# LPC18xx register map
File version: 18
Registers are 32-bit, read-write, reset 0x0 unless marked. A register's access mark holds for its fields unless they carry their own. Offsets are from the block's base; [hi:lo] are bit positions; {n}, {i} and the like mark numbered series.

## TIMER0 — Product name title=UM10430 Chapter title=LPC18xx Timer0/1/2/3 Modification date=1/14/2011 Major revision=0 Minor revision=7
Base 0x40084000
Same registers: TIMER1 0x40085000, TIMER2 0x400C3000, TIMER3 0x400C4000
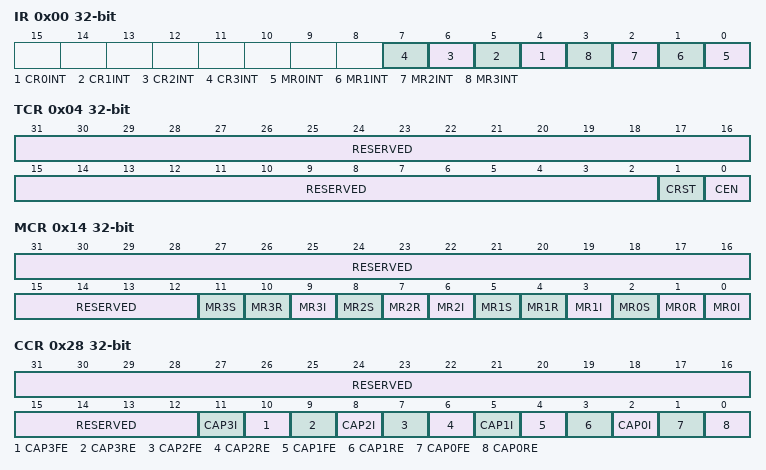
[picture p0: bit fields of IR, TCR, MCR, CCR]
0x00 IR — Interrupt Register. The IR can be written to clear interrupts. The IR can be read to identify which of eight possible interrupt sources are pending.
  [n+4] CR{n}INT (n=0..3) — Interrupt flag for capture channel {n} event.
  [n] MR{n}INT (n=0..3) — Interrupt flag for match channel {n}.
0x04 TCR — Timer Control Register. The TCR is used to control the Timer Counter functions. The Timer Counter can be disabled or reset through the TCR.
  [31:2] RESERVED — Reserved, user software should not write ones to reserved bits. The value read from a reserved bit is not defined.
  [1] CRST — When one, the Timer Counter and the Prescale Counter are synchronously reset on the next positive edge of PCLK. The counters remain reset until TCR[1] is returned to zero.
  [0] CEN — When one, the Timer Counter and Prescale Counter are enabled for counting. When zero, the counters are disabled.
0x08 TC — Timer Counter. The 32 bit TC is incremented every PR+1 cycles of PCLK. The TC is controlled through the TCR.
  [31:0] TC — Timer counter value.
0x0C PR — Prescale Register. The Prescale Counter (below) is equal to this value, the next clock increments the TC and clears the PC.
  [31:0] PM — Prescale counter maximum value.
0x10 PC — Prescale Counter. The 32 bit PC is a counter which is incremented to the value stored in PR. When the value in PR is reached, the TC is incremented and the PC is cleared. The PC is observable and controllable through the bus interface.
  [31:0] PC — Prescale counter value.
0x14 MCR — Match Control Register. The MCR is used to control if an interrupt is generated and if the TC is reset when a Match occurs.
  [31:12] RESERVED — Reserved, user software should not write ones to reserved bits. The value read from a reserved bit is not defined.
  [11] MR3S — Stop on MR3
    1=TC_AND_PC_WILL_BE_ST (TC and PC will be stopped and TCR[0] will be set to 0 if MR3 matches the TC.); 0=FEATURE_DISABLED_
  [3n+1] MR{n}R (n=0..3) — Reset on MR{n}
    1=TC_WILL_BE_RESET_IF_ (TC will be reset if MR{n} matches it.); 0=FEATURE_DISABLED_
  [9] MR3I — Interrupt on MR3
    1=INTERRUPT_IS_GENERAT (Interrupt is generated when MR3 matches the value in the TC.); 0=THIS_INTERRUPT_IS_DI (This interrupt is disabled)
  [8] MR2S — Stop on MR2.
    1=TC_AND_PC_WILL_BE_ST (TC and PC will be stopped and TCR[0] will be set to 0 if MR2 matches the TC); 0=FEATURE_DISABLED_
  [6] MR2I — Interrupt on MR2
    1=INTERRUPT_IS_GENERAT (Interrupt is generated when MR2 matches the value in the TC.); 0=INTERRUPT_IS_DISABLE (Interrupt is disabled)
  [5] MR1S — Stop on MR1
    1=TC_AND_PC_WILL_BE_ST (TC and PC will be stopped and TCR[0] will be set to 0 if MR1 matches the TC.); 0=FEATURE_DISABLED_
  [3] MR1I — Interrupt on MR1
    1=INTERRUPT_IS_GENERAT (Interrupt is generated when MR1 matches the value in the TC.); 0=INTERRUPT_IS_DISABLE (Interrupt is disabled.)
  [2] MR0S — Stop on MR0
    1=TC_AND_PC_WILL_BE_ST (TC and PC will be stopped and TCR[0] will be set to 0 if MR0 matches the TC.); 0=FEATURE_DISABLED_
  [0] MR0I — Interrupt on MR0
    1=INTERRUPT_IS_GENERAT (Interrupt is generated when MR0 matches the value in the TC.); 0=INTERRUPT_IS_DISABLE (Interrupt is disabled)
{0x18+4i} MR{i} (i=0..3) — Match Register. MR can be enabled through the MCR to reset the TC, stop both the TC and PC, and/or generate an interrupt every time MR matches the TC.
  [31:0] MATCH — Timer counter match value.
0x28 CCR — Capture Control Register. The CCR controls which edges of the capture inputs are used to load the Capture Registers and whether or not an interrupt is generated when a capture takes place.
  [31:12] RESERVED — Reserved, user software should not write ones to reserved bits. The value read from a reserved bit is not defined.
  [11] CAP3I — Interrupt on CAPn.3 event:
    1=A_CR3_LOAD_DUE_TO_A_ (A CR3 load due to a CAPn.3 event will generate an interrupt.); 0=THIS_FEATURE_IS_DISA (This feature is disabled.)
  [10] CAP3FE — Capture on CAPn.3 falling edge
    1=A_SEQUENCE_OF_1_THEN (A sequence of 1 then 0 on CAPn.3 will cause CR3 to be loaded with the contents of TC.); 0=THIS_FEATURE_IS_DISA (This feature is disabled.)
  [9] CAP3RE — Capture on CAPn.3 rising edge
    1=A_SEQUENCE_OF_0_THEN (A sequence of 0 then 1 on CAPn.3 will cause CR3 to be loaded with the contents of TC.); 0=THIS_FEATURE_IS_DISA (This feature is disabled.)
  [8] CAP2I — Interrupt on CAPn.2 event
    1=A_CR2_LOAD_DUE_TO_A_ (A CR2 load due to a CAPn.2 event will generate an interrupt.); 0=THIS_FEATURE_IS_DISA (This feature is disabled.)
  [7] CAP2FE — Capture on CAPn.2 falling edge:
    1=A_SEQUENCE_OF_1_THEN (A sequence of 1 then 0 on CAPn.2 will cause CR2 to be loaded with the contents of TC.); 0=THIS_FEATURE_IS_DISA (This feature is disabled.)
  [6] CAP2RE — Capture on CAPn.2 rising edge
    1=A_SEQUENCE_OF_0_THEN (A sequence of 0 then 1 on CAPn.2 will cause CR2 to be loaded with the contents of TC.); 0=THIS_FEATURE_IS_DISA (This feature is disabled.)
  [5] CAP1I — Interrupt on CAPn.1 event
    1=A_CR1_LOAD_DUE_TO_A_ (A CR1 load due to a CAPn.1 event will generate an interrupt.); 0=THIS_FEATURE_IS_DISA (This feature is disabled.)
  [4] CAP1FE — Capture on CAPn.1 falling edge
    1=A_SEQUENCE_OF_1_THEN (A sequence of 1 then 0 on CAPn.1 will cause CR1 to be loaded with the contents of TC.); 0=THIS_FEATURE_IS_DISA (This feature is disabled.)
  [3] CAP1RE — Capture on CAPn.1 rising edge
    1=A_SEQUENCE_OF_0_THEN (A sequence of 0 then 1 on CAPn.1 will cause CR1 to be loaded with the contents of TC.); 0=THIS_FEATURE_IS_DISA (This feature is disabled.)
  [2] CAP0I — Interrupt on CAPn.0 event
    1=A_CR0_LOAD_DUE_TO_A_ (A CR0 load due to a CAPn.0 event will generate an interrupt.); 0=THIS_FEATURE_IS_DISA (This feature is disabled.)
  [1] CAP0FE — Capture on CAPn.0 falling edge
    1=A_SEQUENCE_OF_1_THEN (A sequence of 1 then 0 on CAPn.0 will cause CR0 to be loaded with the contents of TC.); 0=THIS_FEATURE_IS_DISA (This feature is disabled.)
  [0] CAP0RE — Capture on CAPn.0 rising edge
    1=A_SEQUENCE_OF_0_THEN (A sequence of 0 then 1 on CAPn.0 will cause CR0 to be loaded with the contents of TC.); 0=THIS_FEATURE_IS_DISA (This feature is disabled.)
{0x2C+4i} CR{i} (i=0..3) — Capture Register. CR is loaded with the value of TC when there is an event on the CAPn.0 input.
  [31:0] CAP — Timer counter capture value.
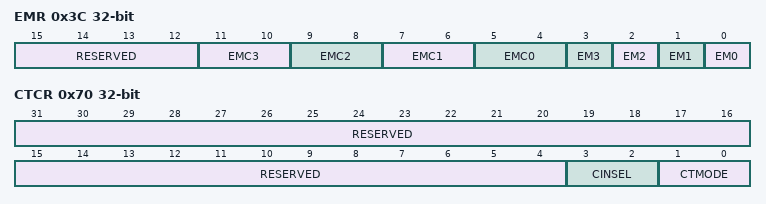
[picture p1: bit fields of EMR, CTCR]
0x3C EMR — External Match Register. The EMR controls the external match pins MATn.0-3 (MAT0.0-3 and MAT1.0-3 respectively).
  [15:12] RESERVED — Reserved, user software should not write ones to reserved bits. The value read from a reserved bit is not defined.
  [2n+5:2n+4] EMC{n} (n=0..3) — External Match Control {n}. Determines the functionality of External Match {n}.
    0=DO_NOTHING_; 1=CLEAR_THE_CORRESPOND (Clear the corresponding External Match bit/output to 0 (MATn.m pin is LOW if pinned out).); 2=SET_THE_CORRESPONDIN (Set the corresponding External Match bit/output to 1 (MATn.m pin is HIGH if pinned out).); 3=TOGGLE_THE_CORRESPON (Toggle the corresponding External Match bit/output.)
  [3] EM3 — External Match 3. When a match occurs between the TC and MR3, this bit can either toggle, go low, go high, or do nothing, depending on bits 11:10 of this register. This bit can be driven onto a MATn.0 pin, in a positive-logic manner (0 = low, 1 = high).
  [2] EM2 — External Match 2. When a match occurs between the TC and MR2, this bit can either toggle, go low, go high, or do nothing, depending on bits 9:8 of this register. This bit can be driven onto a MATn.0 pin, in a positive-logic manner (0 = low, 1 = high).
  [1] EM1 — External Match 1. When a match occurs between the TC and MR1, this bit can either toggle, go low, go high, or do nothing, depending on bits 7:6 of this register. This bit can be driven onto a MATn.1 pin, in a positive-logic manner (0 = low, 1 = high).
  [0] EM0 — External Match 0. When a match occurs between the TC and MR0, this bit can either toggle, go low, go high, or do nothing, depending on bits 5:4 of this register. This bit can be driven onto a MATn.0 pin, in a positive-logic manner (0 = low, 1 = high).
0x70 CTCR — Count Control Register. The CTCR selects between Timer and Counter mode, and in Counter mode selects the signal and edge(s) for counting.
  [31:4] RESERVED — Reserved, user software should not write ones to reserved bits. The value read from a reserved bit is not defined.
  [3:2] CINSEL — Count Input Select When bits 1:0 in this register are not 00, these bits select which CAP pin is sampled for clocking:
    0=CAPN_0_FOR_TIMERN; 1=CAPN_1_FOR_TIMERN; 2=CAPN_2_FOR_TIMERN; 3=CAPN_3_FOR_TIMERN_NO (CAPn.3 for TIMERn Note: If Counter mode is selected for a particular CAPn input in the TnCTCR, the 3 bits for that input in the Capture Control Register (TnCCR) must be programmed as 000. However, capture and/or interrupt can be selected for the other 3 CAPn inputs in the same timer.)
  [1:0] CTMODE — Counter/Timer Mode This field selects which rising PCLK edges can increment Timer's Prescale Counter (PC), or clear PC and increment Timer Counter (TC). Timer Mode: the TC is incremented when the Prescale Counter matches the Prescale Register.
    0=TIMER_MODE_EVERY_RI (Timer Mode: every rising PCLK edge); 1=COUNTER_MODE_TC_IS_ (Counter Mode: TC is incremented on rising edges on the CAP input selected by bits 3:2.); 2=COUNTER_MODE_TC_IS_ (Counter Mode: TC is incremented on falling edges on the CAP input selected by bits 3:2.); 3=COUNTER_MODE_TC_IS_ (Counter Mode: TC is incremented on both edges on the CAP input selected by bits 3:2.)
